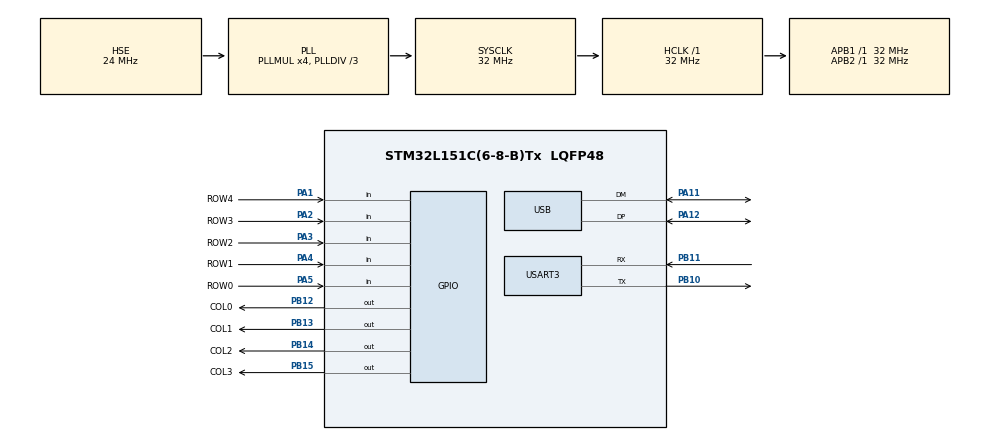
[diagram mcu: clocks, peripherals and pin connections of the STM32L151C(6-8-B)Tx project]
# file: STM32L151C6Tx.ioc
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Mcu.Family=STM32L1
Mcu.Name=STM32L151C(6-8-B)Tx
Mcu.Package=LQFP48
NVIC.PriorityGroup=NVIC_PRIORITYGROUP_4
NVIC.TIM3_IRQn=true\:0\:0\:false\:false\:true\:true\:true
NVIC.USB_HP_IRQn=true\:0\:0\:false\:false\:true\:true\:true
NVIC.USB_LP_IRQn=true\:0\:0\:false\:false\:true\:false\:true
PA1.GPIO_Label=ROW4
PA1.GPIO_PuPd=GPIO_PULLUP
PA1.Signal=GPIO_Input
PA11.Mode=Device
PA11.Signal=USB_DM
PA12.Mode=Device
PA12.Signal=USB_DP
PA13.Signal=SYS_JTMS-SWDIO
PA14.Signal=SYS_JTCK-SWCLK
PA2.GPIO_Label=ROW3
PA2.GPIO_PuPd=GPIO_PULLUP
PA2.Signal=GPIO_Input
PA3.GPIO_Label=ROW2
PA3.GPIO_PuPd=GPIO_PULLUP
PA3.Signal=GPIO_Input
PA4.GPIO_Label=ROW1
PA4.GPIO_PuPd=GPIO_PULLUP
PA4.Signal=GPIO_Input
PA5.GPIO_Label=ROW0
PA5.GPIO_PuPd=GPIO_PULLUP
PA5.Signal=GPIO_Input
PB10.Mode=Asynchronous
PB10.Signal=USART3_TX
PB11.Mode=Asynchronous
PB11.Signal=USART3_RX
PB12.GPIO_Label=COL0
PB12.Signal=GPIO_Output
PB13.GPIO_Label=COL1
PB13.Signal=GPIO_Output
PB14.GPIO_Label=COL2
PB14.Signal=GPIO_Output
PB15.GPIO_Label=COL3
PB15.Signal=GPIO_Output
PH0-OSC_IN.Mode=HSE-External-Oscillator
PH0-OSC_IN.Signal=RCC_OSC_IN
PH1-OSC_OUT.Mode=HSE-External-Oscillator
PH1-OSC_OUT.Signal=RCC_OSC_OUT
ProjectManager.HeapSize=0x200
ProjectManager.StackSize=0x400
ProjectManager.TargetToolchain=STM32CubeIDE
RCC.48MHZClocksFreq_Value=48000000
RCC.AHBFreq_Value=32000000
RCC.APB1Freq_Value=32000000
RCC.APB1TimFreq_Value=32000000
RCC.APB2Freq_Value=32000000
RCC.APB2TimFreq_Value=32000000
RCC.HCLKFreq_Value=32000000
RCC.HSE_VALUE=24000000
RCC.HSI_VALUE=16000000
RCC.LSE_VALUE=32768
RCC.MSI_VALUE=2097000
RCC.PLLDIV=RCC_PLL_DIV3
RCC.PLLMUL=RCC_PLL_MUL4
RCC.SYSCLKFreq_VALUE=32000000
RCC.SYSCLKSource=RCC_SYSCLKSOURCE_PLLCLK
RCC.VCOOutputFreq_Value=96000000
TIM3.Period=999
TIM3.Prescaler=31
USART3.VirtualMode=VM_ASYNC
USB_DEVICE.CLASS_NAME_FS=HID
USB_DEVICE.MANUFACTURER_STRING=Ryan-Mah-Numpad
USB_DEVICE.PRODUCT_STRING_HID_FS=Ryan-Mah-Numpad
USB_DEVICE.VirtualMode=Hid
USB_DEVICE.VirtualModeFS=Hid_FS
VP_TIM3_VS_ClockSourceINT.Mode=Internal
VP_USB_DEVICE_VS_USB_DEVICE_HID_FS.Mode=HID_FS
board=custom

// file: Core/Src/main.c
/* USER CODE BEGIN Header */
/**
  ******************************************************************************
  * @file           : main.c
  * @brief          : Main program body
  ******************************************************************************
  * @attention
  *
  * <h2><center>&copy; Copyright (c) 2021 STMicroelectronics.
  * All rights reserved.</center></h2>
  *
  * This software component is licensed by ST under Ultimate Liberty license
  * SLA0044, the "License"; You may not use this file except in compliance with
  * the License. You may obtain a copy of the License at:
  *                             www.st.com/SLA0044
  *
  ******************************************************************************
  */
/* USER CODE END Header */
#include "main.h"
#include "usb_device.h"

/* USER CODE BEGIN Includes */
#include <stdio.h>
#include "keyboard_entry.h"
/* USER CODE END Includes */

TIM_HandleTypeDef htim3;

UART_HandleTypeDef huart3;

void SystemClock_Config(void);
static void MX_GPIO_Init(void);
static void MX_USART3_UART_Init(void);
static void MX_TIM3_Init(void);

int main(void)
{

  /* MCU Configuration--------------------------------------------------------*/

  /* Reset of all peripherals, Initializes the Flash interface and the Systick. */
  HAL_Init();

  /* Configure the system clock */
  SystemClock_Config();

  /* Initialize all configured peripherals */
  MX_GPIO_Init();
  MX_USART3_UART_Init();
  MX_USB_DEVICE_Init();
  MX_TIM3_Init();
  /* USER CODE BEGIN 2 */
  return keyboard_entry();
  /* USER CODE END 2 */

  /* Infinite loop */
  while (1)
  {

  }
}

void SystemClock_Config(void)
{
  RCC_OscInitTypeDef RCC_OscInitStruct = {0};
  RCC_ClkInitTypeDef RCC_ClkInitStruct = {0};

  /** Configure the main internal regulator output voltage
  */
  __HAL_PWR_VOLTAGESCALING_CONFIG(PWR_REGULATOR_VOLTAGE_SCALE1);
  /** Initializes the RCC Oscillators according to the specified parameters
  * in the RCC_OscInitTypeDef structure.
  */
  RCC_OscInitStruct.OscillatorType = RCC_OSCILLATORTYPE_HSE;
  RCC_OscInitStruct.HSEState = RCC_HSE_ON;
  RCC_OscInitStruct.PLL.PLLState = RCC_PLL_ON;
  RCC_OscInitStruct.PLL.PLLSource = RCC_PLLSOURCE_HSE;
  RCC_OscInitStruct.PLL.PLLMUL = RCC_PLL_MUL4;
  RCC_OscInitStruct.PLL.PLLDIV = RCC_PLL_DIV3;
  if (HAL_RCC_OscConfig(&RCC_OscInitStruct) != HAL_OK)
  {
    Error_Handler();
  }
  /** Initializes the CPU, AHB and APB buses clocks
  */
  RCC_ClkInitStruct.ClockType = RCC_CLOCKTYPE_HCLK|RCC_CLOCKTYPE_SYSCLK
                              |RCC_CLOCKTYPE_PCLK1|RCC_CLOCKTYPE_PCLK2;
  RCC_ClkInitStruct.SYSCLKSource = RCC_SYSCLKSOURCE_PLLCLK;
  RCC_ClkInitStruct.AHBCLKDivider = RCC_SYSCLK_DIV1;
  RCC_ClkInitStruct.APB1CLKDivider = RCC_HCLK_DIV1;
  RCC_ClkInitStruct.APB2CLKDivider = RCC_HCLK_DIV1;

  if (HAL_RCC_ClockConfig(&RCC_ClkInitStruct, FLASH_LATENCY_1) != HAL_OK)
  {
    Error_Handler();
  }
}

static void MX_TIM3_Init(void)
{

  TIM_ClockConfigTypeDef sClockSourceConfig = {0};
  TIM_MasterConfigTypeDef sMasterConfig = {0};

  htim3.Instance = TIM3;
  htim3.Init.Prescaler = 31;
  htim3.Init.CounterMode = TIM_COUNTERMODE_UP;
  htim3.Init.Period = 999;
  htim3.Init.ClockDivision = TIM_CLOCKDIVISION_DIV1;
  htim3.Init.AutoReloadPreload = TIM_AUTORELOAD_PRELOAD_DISABLE;
  if (HAL_TIM_Base_Init(&htim3) != HAL_OK)
  {
    Error_Handler();
  }
  sClockSourceConfig.ClockSource = TIM_CLOCKSOURCE_INTERNAL;
  if (HAL_TIM_ConfigClockSource(&htim3, &sClockSourceConfig) != HAL_OK)
  {
    Error_Handler();
  }
  sMasterConfig.MasterOutputTrigger = TIM_TRGO_RESET;
  sMasterConfig.MasterSlaveMode = TIM_MASTERSLAVEMODE_DISABLE;
  if (HAL_TIMEx_MasterConfigSynchronization(&htim3, &sMasterConfig) != HAL_OK)
  {
    Error_Handler();
  }

}

static void MX_USART3_UART_Init(void)
{

  huart3.Instance = USART3;
  huart3.Init.BaudRate = 115200;
  huart3.Init.WordLength = UART_WORDLENGTH_8B;
  huart3.Init.StopBits = UART_STOPBITS_1;
  huart3.Init.Parity = UART_PARITY_NONE;
  huart3.Init.Mode = UART_MODE_TX_RX;
  huart3.Init.HwFlowCtl = UART_HWCONTROL_NONE;
  huart3.Init.OverSampling = UART_OVERSAMPLING_16;
  if (HAL_UART_Init(&huart3) != HAL_OK)
  {
    Error_Handler();
  }

}

static void MX_GPIO_Init(void)
{
  GPIO_InitTypeDef GPIO_InitStruct = {0};

  /* GPIO Ports Clock Enable */
  __HAL_RCC_GPIOH_CLK_ENABLE();
  __HAL_RCC_GPIOA_CLK_ENABLE();
  __HAL_RCC_GPIOB_CLK_ENABLE();

  /*Configure GPIO pin Output Level */
  HAL_GPIO_WritePin(GPIOB, COL0_Pin|COL1_Pin|COL2_Pin|COL3_Pin, GPIO_PIN_RESET);

  /*Configure GPIO pins : ROW4_Pin ROW3_Pin ROW2_Pin ROW1_Pin
                           ROW0_Pin */
  GPIO_InitStruct.Pin = ROW4_Pin|ROW3_Pin|ROW2_Pin|ROW1_Pin
                          |ROW0_Pin;
  GPIO_InitStruct.Mode = GPIO_MODE_INPUT;
  GPIO_InitStruct.Pull = GPIO_PULLUP;
  HAL_GPIO_Init(GPIOA, &GPIO_InitStruct);

  /*Configure GPIO pins : COL0_Pin COL1_Pin COL2_Pin COL3_Pin */
  GPIO_InitStruct.Pin = COL0_Pin|COL1_Pin|COL2_Pin|COL3_Pin;
  GPIO_InitStruct.Mode = GPIO_MODE_OUTPUT_PP;
  GPIO_InitStruct.Pull = GPIO_NOPULL;
  GPIO_InitStruct.Speed = GPIO_SPEED_FREQ_LOW;
  HAL_GPIO_Init(GPIOB, &GPIO_InitStruct);

}

void Error_Handler(void)
{
  /* USER CODE BEGIN Error_Handler_Debug */
  /* User can add his own implementation to report the HAL error return state */
  printf("ERROR!!! Entering Error_Handler()...\r\n");
  __disable_irq();
  while (1)
  {
  }
  /* USER CODE END Error_Handler_Debug */
}

/************************ (C) COPYRIGHT STMicroelectronics *****END OF FILE****/
